# LRFDRFE register map
Vendor: Texas Instruments
Peripheral module from a debugger description file (folder CC27xxx7).
Registers are 32-bit, access per field, reset 0x0 unless marked. A register's access mark holds for its fields unless they carry their own. Offsets are as the file gives them; lines under a group give offsets from that group; [hi:lo] are bit positions; {n}, {i} and the like mark numbered series; 'fields as' and 'values as' point back to an identical list; <NAME> marks a mode.

## LRFDRFE (part 1 of 2)
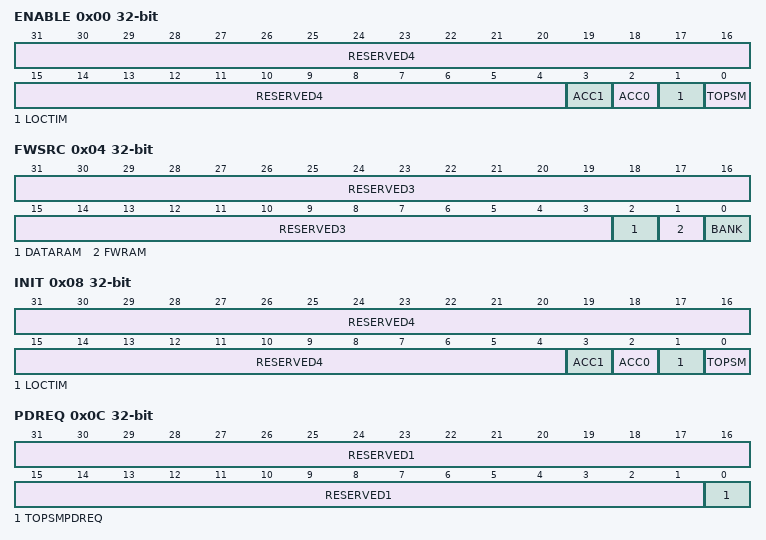
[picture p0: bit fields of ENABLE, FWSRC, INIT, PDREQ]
0x00 ENABLE — Internal. Only to be used through TI provided API.
  [31:4] RESERVED4 ro — Internal. Only to be used through TI provided API.
  [3] ACC1 rw — Internal. Only to be used through TI provided API.
    1=EN (Internal. Only to be used through TI provided API.); 0=DIS (Internal. Only to be used through TI provided API.)
  [2] ACC0 rw — Internal. Only to be used through TI provided API.
    values as ACC1
  [1] LOCTIM rw — Internal. Only to be used through TI provided API.
    values as ACC1
  [0] TOPSM rw — Internal. Only to be used through TI provided API.
    values as ACC1
0x04 FWSRC — Internal. Only to be used through TI provided API.
  [31:3] RESERVED3 ro — Internal. Only to be used through TI provided API.
  [2] DATARAM rw — Internal. Only to be used through TI provided API.
    1=S2RRAM (Internal. Only to be used through TI provided API.); 0=RFERAM (Internal. Only to be used through TI provided API.)
  [1] FWRAM rw — Internal. Only to be used through TI provided API.
    values as DATARAM
  [0] BANK rw — Internal. Only to be used through TI provided API.
    1=ONE (Internal. Only to be used through TI provided API.); 0=ZERO (Internal. Only to be used through TI provided API.)
0x08 INIT — Internal. Only to be used through TI provided API.
  [31:4] RESERVED4 ro — Internal. Only to be used through TI provided API.
  [3] ACC1 wo — Internal. Only to be used through TI provided API.
    1=RESET (Internal. Only to be used through TI provided API.); 0=NO_EFFECT (Internal. Only to be used through TI provided API.)
  [2] ACC0 wo — Internal. Only to be used through TI provided API.
    values as ACC1
  [1] LOCTIM wo — Internal. Only to be used through TI provided API.
    values as ACC1
  [0] TOPSM wo — Internal. Only to be used through TI provided API.
    values as ACC1
0x0C PDREQ — Internal. Only to be used through TI provided API.
  [31:1] RESERVED1 ro — Internal. Only to be used through TI provided API.
  [0] TOPSMPDREQ rw — Internal. Only to be used through TI provided API.
    values as FWSRC.BANK
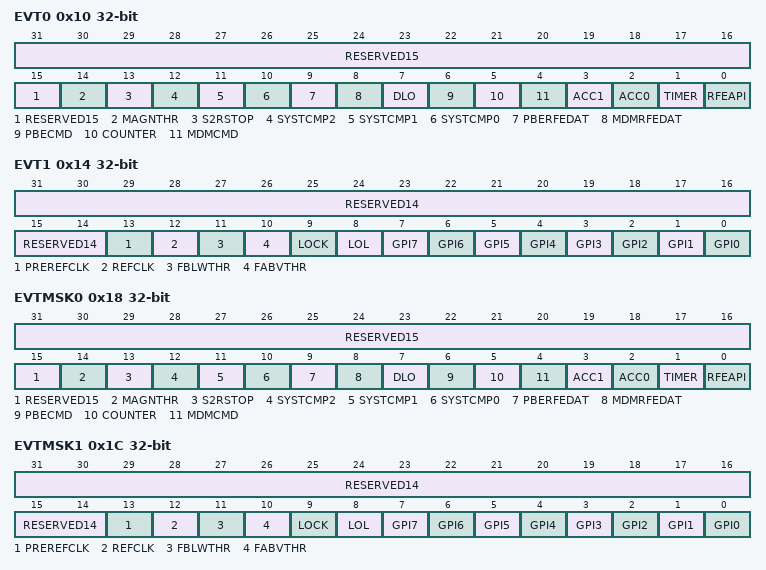
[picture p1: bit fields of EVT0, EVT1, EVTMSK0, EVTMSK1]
0x10 EVT0 ro — Internal. Only to be used through TI provided API.
  [31:15] RESERVED15 — Internal. Only to be used through TI provided API.
  [14] MAGNTHR — Internal. Only to be used through TI provided API.
    values as FWSRC.BANK
  [13] S2RSTOP — Internal. Only to be used through TI provided API.
    values as FWSRC.BANK
  [12] SYSTCMP2 — Internal. Only to be used through TI provided API.
    values as FWSRC.BANK
  [11] SYSTCMP1 — Internal. Only to be used through TI provided API.
    values as FWSRC.BANK
  [10] SYSTCMP0 — Internal. Only to be used through TI provided API.
    values as FWSRC.BANK
  [9] PBERFEDAT — Internal. Only to be used through TI provided API.
    values as FWSRC.BANK
  [8] MDMRFEDAT — Internal. Only to be used through TI provided API.
    values as FWSRC.BANK
  [7] DLO — Internal. Only to be used through TI provided API.
    values as FWSRC.BANK
  [6] PBECMD — Internal. Only to be used through TI provided API.
    values as FWSRC.BANK
  [5] COUNTER — Internal. Only to be used through TI provided API.
    values as FWSRC.BANK
  [4] MDMCMD — Internal. Only to be used through TI provided API.
    values as FWSRC.BANK
  [3] ACC1 — Internal. Only to be used through TI provided API.
    values as FWSRC.BANK
  [2] ACC0 — Internal. Only to be used through TI provided API.
    values as FWSRC.BANK
  [1] TIMER — Internal. Only to be used through TI provided API.
    values as FWSRC.BANK
  [0] RFEAPI — Internal. Only to be used through TI provided API.
    values as FWSRC.BANK
0x14 EVT1 ro — Internal. Only to be used through TI provided API.
  [31:14] RESERVED14 — Internal. Only to be used through TI provided API.
  [13] PREREFCLK — Internal. Only to be used through TI provided API.
    values as FWSRC.BANK
  [12] REFCLK — Internal. Only to be used through TI provided API.
    values as FWSRC.BANK
  [11] FBLWTHR — Internal. Only to be used through TI provided API.
    values as FWSRC.BANK
  [10] FABVTHR — Internal. Only to be used through TI provided API.
    values as FWSRC.BANK
  [9] LOCK — Internal. Only to be used through TI provided API.
    values as FWSRC.BANK
  [8] LOL — Internal. Only to be used through TI provided API.
    values as FWSRC.BANK
  [n] GPI{n} (n=0..7) — Internal. Only to be used through TI provided API.
    values as FWSRC.BANK
0x18 EVTMSK0 — Internal. Only to be used through TI provided API.
  [31:15] RESERVED15 ro — Internal. Only to be used through TI provided API.
  [14] MAGNTHR rw — Internal. Only to be used through TI provided API.
    values as ENABLE.ACC1
  [13] S2RSTOP rw — Internal. Only to be used through TI provided API.
    values as ENABLE.ACC1
  [12] SYSTCMP2 rw — Internal. Only to be used through TI provided API.
    values as ENABLE.ACC1
  [11] SYSTCMP1 rw — Internal. Only to be used through TI provided API.
    values as ENABLE.ACC1
  [10] SYSTCMP0 rw — Internal. Only to be used through TI provided API.
    values as ENABLE.ACC1
  [9] PBERFEDAT rw — Internal. Only to be used through TI provided API.
    values as ENABLE.ACC1
  [8] MDMRFEDAT rw — Internal. Only to be used through TI provided API.
    values as ENABLE.ACC1
  [7] DLO rw — Internal. Only to be used through TI provided API.
    values as ENABLE.ACC1
  [6] PBECMD rw — Internal. Only to be used through TI provided API.
    values as ENABLE.ACC1
  [5] COUNTER rw — Internal. Only to be used through TI provided API.
    values as ENABLE.ACC1
  [4] MDMCMD rw — Internal. Only to be used through TI provided API.
    values as ENABLE.ACC1
  [3] ACC1 rw — Internal. Only to be used through TI provided API.
    values as ENABLE.ACC1
  [2] ACC0 rw — Internal. Only to be used through TI provided API.
    values as ENABLE.ACC1
  [1] TIMER rw — Internal. Only to be used through TI provided API.
    values as ENABLE.ACC1
  [0] RFEAPI rw — Internal. Only to be used through TI provided API.
    values as ENABLE.ACC1
0x1C EVTMSK1 — Internal. Only to be used through TI provided API.
  [31:14] RESERVED14 ro — Internal. Only to be used through TI provided API.
  [13] PREREFCLK rw — Internal. Only to be used through TI provided API.
    values as ENABLE.ACC1
  [12] REFCLK rw — Internal. Only to be used through TI provided API.
    values as ENABLE.ACC1
  [11] FBLWTHR rw — Internal. Only to be used through TI provided API.
    values as ENABLE.ACC1
  [10] FABVTHR rw — Internal. Only to be used through TI provided API.
    values as ENABLE.ACC1
  [9] LOCK rw — Internal. Only to be used through TI provided API.
    values as ENABLE.ACC1
  [8] LOL rw — Internal. Only to be used through TI provided API.
    values as ENABLE.ACC1
  [n] GPI{n} rw (n=0..7) — Internal. Only to be used through TI provided API.
    values as ENABLE.ACC1
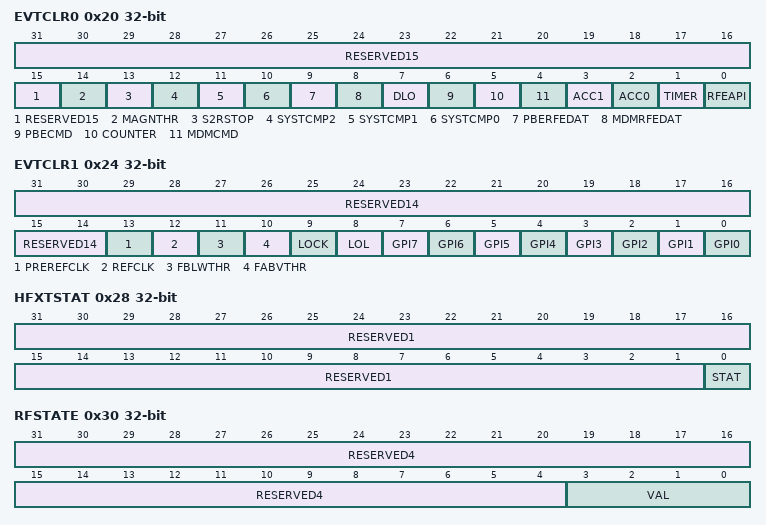
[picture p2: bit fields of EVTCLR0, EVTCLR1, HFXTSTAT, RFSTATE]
0x20 EVTCLR0 — Internal. Only to be used through TI provided API.
  [31:15] RESERVED15 ro — Internal. Only to be used through TI provided API.
  [14] MAGNTHR wo — Internal. Only to be used through TI provided API.
    values as FWSRC.BANK
  [13] S2RSTOP wo — Internal. Only to be used through TI provided API.
    values as FWSRC.BANK
  [12] SYSTCMP2 wo — Internal. Only to be used through TI provided API.
    values as FWSRC.BANK
  [11] SYSTCMP1 wo — Internal. Only to be used through TI provided API.
    values as FWSRC.BANK
  [10] SYSTCMP0 wo — Internal. Only to be used through TI provided API.
    values as FWSRC.BANK
  [9] PBERFEDAT wo — Internal. Only to be used through TI provided API.
    values as FWSRC.BANK
  [8] MDMRFEDAT wo — Internal. Only to be used through TI provided API.
    values as FWSRC.BANK
  [7] DLO wo — Internal. Only to be used through TI provided API.
    values as FWSRC.BANK
  [6] PBECMD wo — Internal. Only to be used through TI provided API.
    values as FWSRC.BANK
  [5] COUNTER wo — Internal. Only to be used through TI provided API.
    values as FWSRC.BANK
  [4] MDMCMD wo — Internal. Only to be used through TI provided API.
    values as FWSRC.BANK
  [3] ACC1 wo — Internal. Only to be used through TI provided API.
    values as FWSRC.BANK
  [2] ACC0 wo — Internal. Only to be used through TI provided API.
    values as FWSRC.BANK
  [1] TIMER wo — Internal. Only to be used through TI provided API.
    values as FWSRC.BANK
  [0] RFEAPI wo — Internal. Only to be used through TI provided API.
    values as FWSRC.BANK
0x24 EVTCLR1 — Internal. Only to be used through TI provided API.
  [31:14] RESERVED14 ro — Internal. Only to be used through TI provided API.
  [13] PREREFCLK wo — Internal. Only to be used through TI provided API.
    values as FWSRC.BANK
  [12] REFCLK wo — Internal. Only to be used through TI provided API.
    values as FWSRC.BANK
  [11] FBLWTHR wo — Internal. Only to be used through TI provided API.
    values as FWSRC.BANK
  [10] FABVTHR wo — Internal. Only to be used through TI provided API.
    values as FWSRC.BANK
  [9] LOCK wo — Internal. Only to be used through TI provided API.
    values as FWSRC.BANK
  [8] LOL wo — Internal. Only to be used through TI provided API.
    values as FWSRC.BANK
  [n] GPI{n} wo (n=0..7) — Internal. Only to be used through TI provided API.
    values as FWSRC.BANK
0x28 HFXTSTAT ro — Internal. Only to be used through TI provided API.
  [31:1] RESERVED1 — Internal. Only to be used through TI provided API.
  [0] STAT — Internal. Only to be used through TI provided API.
    1=QUAL (Internal. Only to be used through TI provided API.); 0=NONQUAL (Internal. Only to be used through TI provided API.)
0x30 RFSTATE — Internal. Only to be used through TI provided API.
  [31:4] RESERVED4 ro — Internal. Only to be used through TI provided API.
  [3:0] VAL rw — Internal. Only to be used through TI provided API.
    3=RX (Internal. Only to be used through TI provided API.); 2=TX (Internal. Only to be used through TI provided API.); 1=SYNTH (Internal. Only to be used through TI provided API.); 0=IDLE (Internal. Only to be used through TI provided API.)
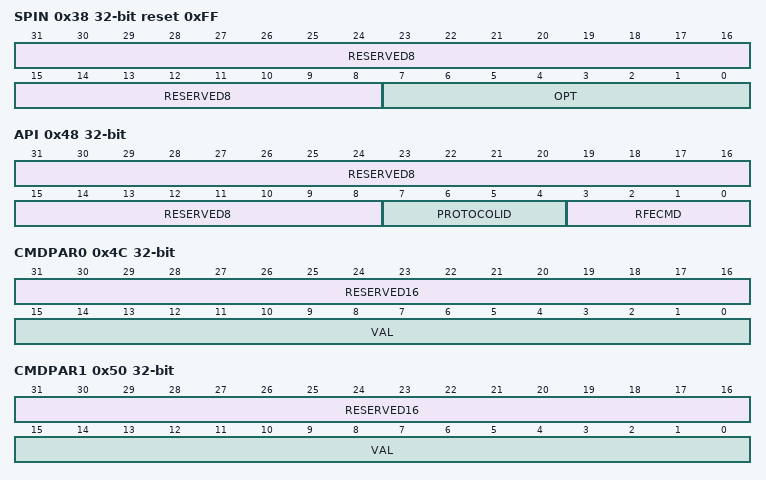
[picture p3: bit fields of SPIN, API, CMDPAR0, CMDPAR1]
0x38 SPIN ro reset 0xFF — Internal. Only to be used through TI provided API.
  [31:8] RESERVED8 — Internal. Only to be used through TI provided API.
  [7:0] OPT — Internal. Only to be used through TI provided API.
    255=ALLONES (Internal. Only to be used through TI provided API.); 0=ALLZEROS (Internal. Only to be used through TI provided API.)
0x48 API ro — Internal. Only to be used through TI provided API.
  [31:8] RESERVED8 — Internal. Only to be used through TI provided API.
  [7:4] PROTOCOLID — Internal. Only to be used through TI provided API.
    15=ALLONES (Internal. Only to be used through TI provided API.); 0=ALLZEROS (Internal. Only to be used through TI provided API.)
  [3:0] RFECMD — Internal. Only to be used through TI provided API.
    values as PROTOCOLID
0x4C CMDPAR0 ro — Internal. Only to be used through TI provided API.
  [31:16] RESERVED16 — Internal. Only to be used through TI provided API.
  [15:0] VAL — Internal. Only to be used through TI provided API.
    0xFFFF=ALLONES (Internal. Only to be used through TI provided API.); 0=ALLZEROS (Internal. Only to be used through TI provided API.)
0x50 CMDPAR1 ro — Internal. Only to be used through TI provided API.
  fields as CMDPAR0
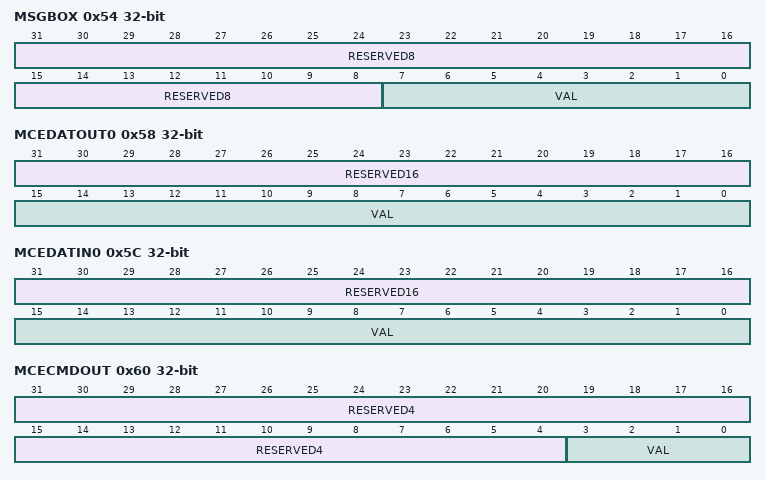
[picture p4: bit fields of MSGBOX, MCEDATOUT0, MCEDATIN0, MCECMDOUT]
0x54 MSGBOX — Internal. Only to be used through TI provided API.
  [31:8] RESERVED8 ro — Internal. Only to be used through TI provided API.
  [7:0] VAL rw — Internal. Only to be used through TI provided API.
    values as SPIN.OPT
0x58 MCEDATOUT0 — Internal. Only to be used through TI provided API.
  [31:16] RESERVED16 ro — Internal. Only to be used through TI provided API.
  [15:0] VAL rw — Internal. Only to be used through TI provided API.
    values as CMDPAR0.VAL
0x5C MCEDATIN0 ro — Internal. Only to be used through TI provided API.
  fields as CMDPAR0
0x60 MCECMDOUT — Internal. Only to be used through TI provided API.
  [31:4] RESERVED4 ro — Internal. Only to be used through TI provided API.
  [3:0] VAL rw — Internal. Only to be used through TI provided API.
    values as API.PROTOCOLID
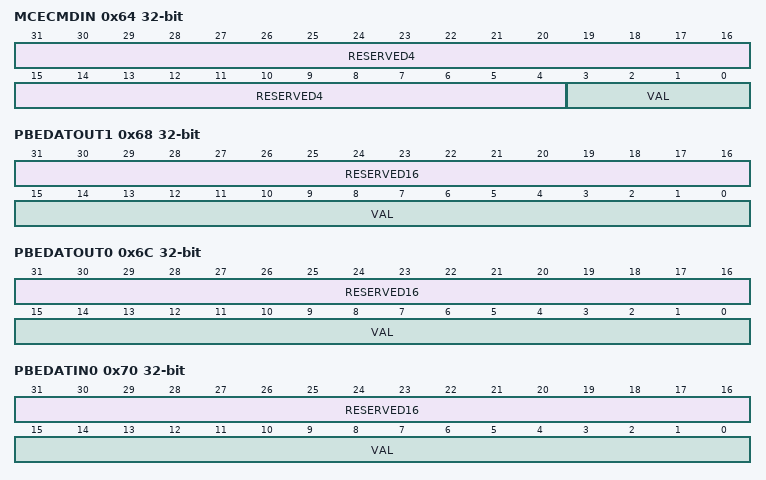
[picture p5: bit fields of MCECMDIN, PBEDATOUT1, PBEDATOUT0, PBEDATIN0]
0x64 MCECMDIN ro — Internal. Only to be used through TI provided API.
  [31:4] RESERVED4 — Internal. Only to be used through TI provided API.
  [3:0] VAL — Internal. Only to be used through TI provided API.
    values as API.PROTOCOLID
0x68 PBEDATOUT1 — Internal. Only to be used through TI provided API.
  fields as MCEDATOUT0
0x6C PBEDATOUT0 — Internal. Only to be used through TI provided API.
  fields as MCEDATOUT0
0x70 PBEDATIN0 ro — Internal. Only to be used through TI provided API.
  fields as CMDPAR0
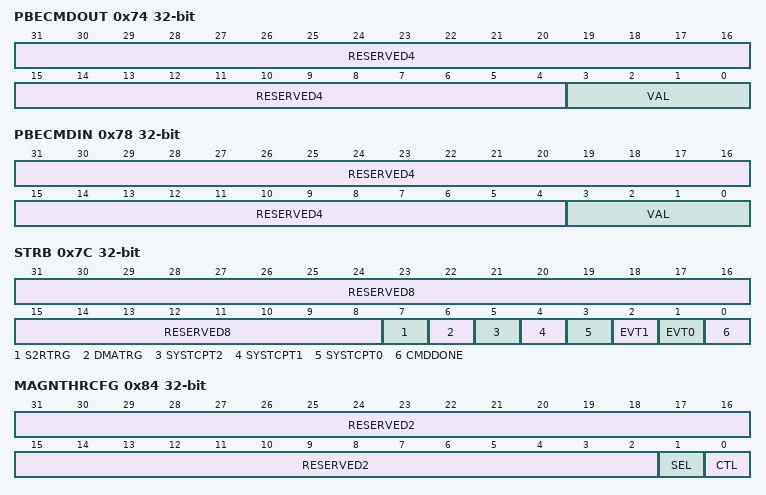
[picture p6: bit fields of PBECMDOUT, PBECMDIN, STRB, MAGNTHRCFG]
0x74 PBECMDOUT — Internal. Only to be used through TI provided API.
  fields as MCECMDOUT
0x78 PBECMDIN ro — Internal. Only to be used through TI provided API.
  fields as MCECMDIN
0x7C STRB — Internal. Only to be used through TI provided API.
  [31:8] RESERVED8 ro — Internal. Only to be used through TI provided API.
  [7] S2RTRG wo — Internal. Only to be used through TI provided API.
    values as FWSRC.BANK
  [6] DMATRG wo — Internal. Only to be used through TI provided API.
    values as FWSRC.BANK
  [5] SYSTCPT2 wo — Internal. Only to be used through TI provided API.
    values as FWSRC.BANK
  [4] SYSTCPT1 wo — Internal. Only to be used through TI provided API.
    values as FWSRC.BANK
  [3] SYSTCPT0 wo — Internal. Only to be used through TI provided API.
    values as FWSRC.BANK
  [2] EVT1 wo — Internal. Only to be used through TI provided API.
    values as FWSRC.BANK
  [1] EVT0 wo — Internal. Only to be used through TI provided API.
    values as FWSRC.BANK
  [0] CMDDONE wo — Internal. Only to be used through TI provided API.
    1=YES (Internal. Only to be used through TI provided API.); 0=NO (Internal. Only to be used through TI provided API.)
0x84 MAGNTHRCFG — Internal. Only to be used through TI provided API.
  [31:2] RESERVED2 ro — Internal. Only to be used through TI provided API.
  [1] SEL rw — Internal. Only to be used through TI provided API.
    1=MAGNACC1 (Internal. Only to be used through TI provided API.); 0=MAGNACC0 (Internal. Only to be used through TI provided API.)
  [0] CTL rw — Internal. Only to be used through TI provided API.
    values as ENABLE.ACC1
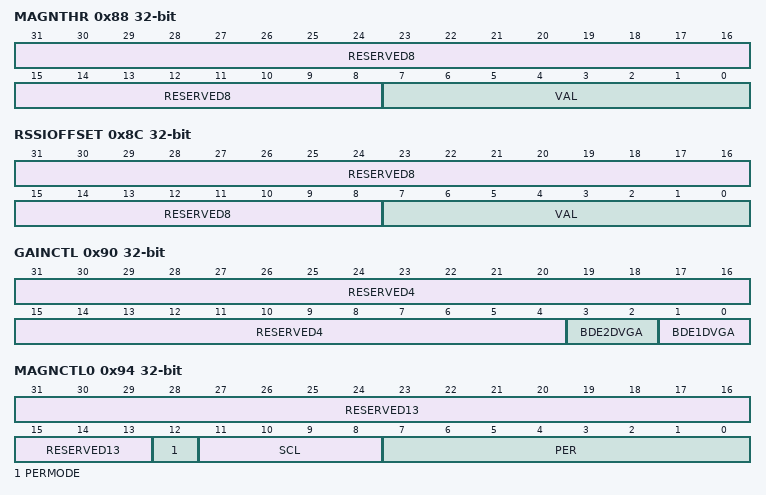
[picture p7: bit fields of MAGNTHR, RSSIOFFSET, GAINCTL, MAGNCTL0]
0x88 MAGNTHR — Internal. Only to be used through TI provided API.
  fields as MSGBOX
0x8C RSSIOFFSET — Internal. Only to be used through TI provided API.
  fields as MSGBOX
0x90 GAINCTL — Internal. Only to be used through TI provided API.
  [31:4] RESERVED4 ro — Internal. Only to be used through TI provided API.
  [3:2] BDE2DVGA rw — Internal. Only to be used through TI provided API.
    3=GAIN8 (Internal. Only to be used through TI provided API.); 2=GAIN4 (Internal. Only to be used through TI provided API.); 1=GAIN2 (Internal. Only to be used through TI provided API.); 0=GAIN1 (Internal. Only to be used through TI provided API.)
  [1:0] BDE1DVGA rw — Internal. Only to be used through TI provided API.
    values as BDE2DVGA
0x94 MAGNCTL0 — Internal. Only to be used through TI provided API.
  [31:13] RESERVED13 ro — Internal. Only to be used through TI provided API.
  [12] PERMODE rw — Internal. Only to be used through TI provided API.
    1=PERIODIC (Internal. Only to be used through TI provided API.); 0=ONESHOT (Internal. Only to be used through TI provided API.)
  [11:8] SCL rw — Internal. Only to be used through TI provided API.
    8=DIV256 (Internal. Only to be used through TI provided API.); 7=DIV128 (Internal. Only to be used through TI provided API.); 6=DIV64 (Internal. Only to be used through TI provided API.); 5=DIV32 (Internal. Only to be used through TI provided API.); 4=DIV16 (Internal. Only to be used through TI provided API.); 3=DIV8 (Internal. Only to be used through TI provided API.); 2=DIV4 (Internal. Only to be used through TI provided API.); 1=DIV2 (Internal. Only to be used through TI provided API.); 0=DIV1 (Internal. Only to be used through TI provided API.)
  [7:0] PER rw — Internal. Only to be used through TI provided API.
    values as SPIN.OPT
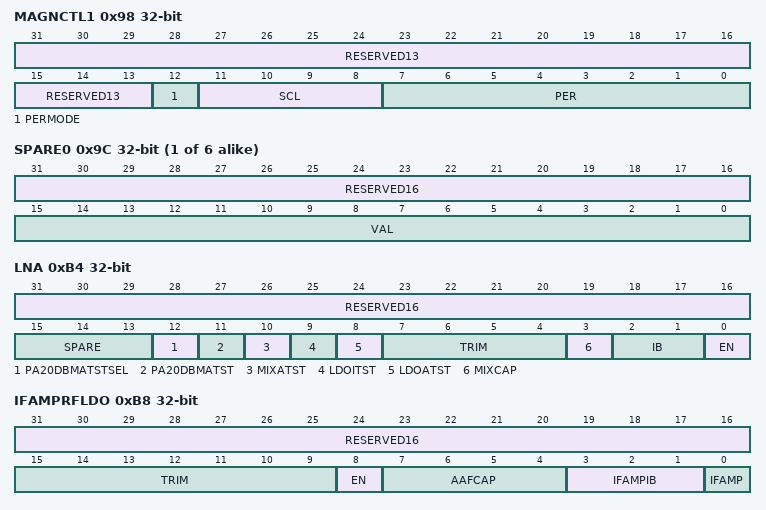
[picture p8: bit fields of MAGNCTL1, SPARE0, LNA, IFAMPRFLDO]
0x98 MAGNCTL1 — Internal. Only to be used through TI provided API.
  fields as MAGNCTL0
{0x9C+4i} SPARE{i} (i=0..5) — Internal. Only to be used through TI provided API.
  fields as MCEDATOUT0
0xB4 LNA — Internal. Only to be used through TI provided API.
  [31:16] RESERVED16 ro — Internal. Only to be used through TI provided API.
  [15:13] SPARE rw — Internal. Only to be used through TI provided API.
    values as ENABLE.ACC1
  [12] PA20DBMATSTSEL rw — Internal. Only to be used through TI provided API.
    1=SECOND (Internal. Only to be used through TI provided API.); 0=FIRST (Internal. Only to be used through TI provided API.)
  [11] PA20DBMATST rw — Internal. Only to be used through TI provided API.
    values as ENABLE.ACC1
  [10] MIXATST rw — Internal. Only to be used through TI provided API.
    values as ENABLE.ACC1
  [9] LDOITST rw — Internal. Only to be used through TI provided API.
    values as ENABLE.ACC1
  [8] LDOATST rw — Internal. Only to be used through TI provided API.
    values as ENABLE.ACC1
  [7:4] TRIM rw — Internal. Only to be used through TI provided API.
    15=ONES (Internal. Only to be used through TI provided API.); 0=ZEROS (Internal. Only to be used through TI provided API.)
  [3] MIXCAP rw — Internal. Only to be used through TI provided API.
    values as ENABLE.ACC1
  [2:1] IB rw — Internal. Only to be used through TI provided API.
    3=MAX (Internal. Only to be used through TI provided API.); 0=MIN (Internal. Only to be used through TI provided API.)
  [0] EN rw — Internal. Only to be used through TI provided API.
    1=ON (Internal. Only to be used through TI provided API.); 0=OFF (Internal. Only to be used through TI provided API.)
0xB8 IFAMPRFLDO — Internal. Only to be used through TI provided API.
  [31:16] RESERVED16 ro — Internal. Only to be used through TI provided API.
  [15:9] TRIM rw — Internal. Only to be used through TI provided API.
    127=BYPASS (Internal. Only to be used through TI provided API.); 126=MAX (Internal. Only to be used through TI provided API.); 0=MIN (Internal. Only to be used through TI provided API.)
  [8] EN rw — Internal. Only to be used through TI provided API.
    values as ENABLE.ACC1
  [7:4] AAFCAP rw — Internal. Only to be used through TI provided API.
    15=MAX (Internal. Only to be used through TI provided API.); 0=MIN (Internal. Only to be used through TI provided API.)
  [3:1] IFAMPIB rw — Internal. Only to be used through TI provided API.
    7=MAX (Internal. Only to be used through TI provided API.); 0=MIN (Internal. Only to be used through TI provided API.)
  [0] IFAMP rw — Internal. Only to be used through TI provided API.
    values as ENABLE.ACC1
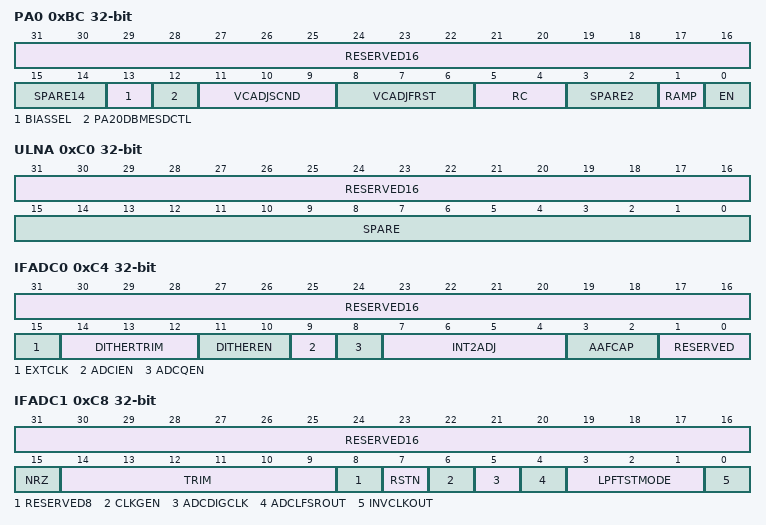
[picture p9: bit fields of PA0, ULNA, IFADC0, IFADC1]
0xBC PA0 — Internal. Only to be used through TI provided API.
  [31:16] RESERVED16 ro — Internal. Only to be used through TI provided API.
  [15:14] SPARE14 rw — Internal. Only to be used through TI provided API.
    values as LNA.IB
  [13] BIASSEL rw — Internal. Only to be used through TI provided API.
    values as FWSRC.BANK
  [12] PA20DBMESDCTL rw — Internal. Only to be used through TI provided API.
    values as FWSRC.BANK
  [11:9] VCADJSCND rw — Internal. Only to be used through TI provided API.
    values as IFAMPRFLDO.IFAMPIB
  [8:6] VCADJFRST rw — Internal. Only to be used through TI provided API.
    values as IFAMPRFLDO.IFAMPIB
  [5:4] RC rw — Internal. Only to be used through TI provided API.
    values as LNA.IB
  [3:2] SPARE2 rw — Internal. Only to be used through TI provided API.
    values as LNA.IB
  [1] RAMP rw — Internal. Only to be used through TI provided API.
    1=UP (Internal. Only to be used through TI provided API.); 0=DOWN (Internal. Only to be used through TI provided API.)
  [0] EN rw — Internal. Only to be used through TI provided API.
    values as ENABLE.ACC1
0xC0 ULNA — Internal. Only to be used through TI provided API.
  [31:16] RESERVED16 ro — Internal. Only to be used through TI provided API.
  [15:0] SPARE rw — Internal. Only to be used through TI provided API.
    values as CMDPAR0.VAL
0xC4 IFADC0 — Internal. Only to be used through TI provided API.
  [31:16] RESERVED16 ro — Internal. Only to be used through TI provided API.
  [15] EXTCLK rw — Internal. Only to be used through TI provided API.
    values as ENABLE.ACC1
  [14:12] DITHERTRIM rw — Internal. Only to be used through TI provided API.
    7=ONES (Internal. Only to be used through TI provided API.); 0=ZEROS (Internal. Only to be used through TI provided API.)
  [11:10] DITHEREN rw — Internal. Only to be used through TI provided API.
    3=ENG (Internal. Only to be used through TI provided API.); 2=ENSD (Internal. Only to be used through TI provided API.); 1=ENS (Internal. Only to be used through TI provided API.); 0=DIS (Internal. Only to be used through TI provided API.)
  [9] ADCIEN rw — Internal. Only to be used through TI provided API.
    values as ENABLE.ACC1
  [8] ADCQEN rw — Internal. Only to be used through TI provided API.
    values as ENABLE.ACC1
  [7:4] INT2ADJ rw — Internal. Only to be used through TI provided API.
    values as LNA.TRIM
  [3:2] AAFCAP rw — Internal. Only to be used through TI provided API.
    values as DITHEREN
  [1:0] RESERVED rw — Internal. Only to be used through TI provided API.
    3=ONES (Internal. Only to be used through TI provided API.); 0=ZEROS (Internal. Only to be used through TI provided API.)
0xC8 IFADC1 — Internal. Only to be used through TI provided API.
  [31:16] RESERVED16 ro — Internal. Only to be used through TI provided API.
  [15] NRZ rw — Internal. Only to be used through TI provided API.
    values as ENABLE.ACC1
  [14:9] TRIM rw — Internal. Only to be used through TI provided API.
    63=ONES (Internal. Only to be used through TI provided API.); 0=ZEROS (Internal. Only to be used through TI provided API.)
  [8] RESERVED8 rw — Internal. Only to be used through TI provided API.
    values as ENABLE.ACC1
  [7] RSTN rw — Internal. Only to be used through TI provided API.
    1=DIS (Internal. Only to be used through TI provided API.); 0=EN (Internal. Only to be used through TI provided API.)
  [6] CLKGEN rw — Internal. Only to be used through TI provided API.
    values as ENABLE.ACC1
  [5] ADCDIGCLK rw — Internal. Only to be used through TI provided API.
    values as ENABLE.ACC1
  [4] ADCLFSROUT rw — Internal. Only to be used through TI provided API.
    values as ENABLE.ACC1
  [3:1] LPFTSTMODE rw — Internal. Only to be used through TI provided API.
    values as ENABLE.ACC1
  [0] INVCLKOUT rw — Internal. Only to be used through TI provided API.
    values as ENABLE.ACC1
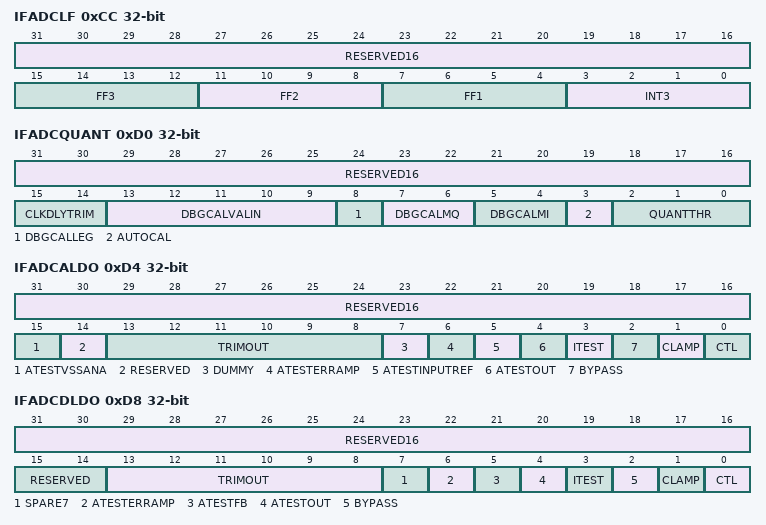
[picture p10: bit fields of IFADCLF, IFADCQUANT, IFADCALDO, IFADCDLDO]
0xCC IFADCLF — Internal. Only to be used through TI provided API.
  [31:16] RESERVED16 ro — Internal. Only to be used through TI provided API.
  [15:12] FF3 rw — Internal. Only to be used through TI provided API.
    values as LNA.TRIM
  [11:8] FF2 rw — Internal. Only to be used through TI provided API.
    values as LNA.TRIM
  [7:4] FF1 rw — Internal. Only to be used through TI provided API.
    values as LNA.TRIM
  [3:0] INT3 rw — Internal. Only to be used through TI provided API.
    values as LNA.TRIM
0xD0 IFADCQUANT — Internal. Only to be used through TI provided API.
  [31:16] RESERVED16 ro — Internal. Only to be used through TI provided API.
  [15:14] CLKDLYTRIM rw — Internal. Only to be used through TI provided API.
    values as IFADC0.RESERVED
  [13:9] DBGCALVALIN rw — Internal. Only to be used through TI provided API.
    31=ONES (Internal. Only to be used through TI provided API.); 0=ZEROS (Internal. Only to be used through TI provided API.)
  [8] DBGCALLEG rw — Internal. Only to be used through TI provided API.
    1=NEG (Internal. Only to be used through TI provided API.); 0=POS (Internal. Only to be used through TI provided API.)
  [7:6] DBGCALMQ rw — Internal. Only to be used through TI provided API.
    3=DBGCAL_QMODB (Internal. Only to be used through TI provided API.); 2=DBGCAL_QMODP (Internal. Only to be used through TI provided API.); 1=DBGCAL_QMODN (Internal. Only to be used through TI provided API.); 0=DBGCAL_QMODZ (Internal. Only to be used through TI provided API.)
  [5:4] DBGCALMI rw — Internal. Only to be used through TI provided API.
    3=DBGCAL_IMODB (Internal. Only to be used through TI provided API.); 2=DBGCAL_IMODP (Internal. Only to be used through TI provided API.); 1=DBGCAL_IMODN (Internal. Only to be used through TI provided API.); 0=DBGCAL_IMODZ (Internal. Only to be used through TI provided API.)
  [3] AUTOCAL rw — Internal. Only to be used through TI provided API.
    values as ENABLE.ACC1
  [2:0] QUANTTHR rw — Internal. Only to be used through TI provided API.
    values as IFADC0.DITHERTRIM
0xD4 IFADCALDO — Internal. Only to be used through TI provided API.
  [31:16] RESERVED16 ro — Internal. Only to be used through TI provided API.
  [15] ATESTVSSANA rw — Internal. Only to be used through TI provided API.
    values as ENABLE.ACC1
  [14] RESERVED rw — Internal. Only to be used through TI provided API.
    1=ONES (Internal. Only to be used through TI provided API.); 0=ZEROS (Internal. Only to be used through TI provided API.)
  [13:8] TRIMOUT rw — Internal. Only to be used through TI provided API.
    values as IFADC1.TRIM
  [7] DUMMY rw — Internal. Only to be used through TI provided API.
    1=DISN (Internal. Only to be used through TI provided API.); 0=ENN (Internal. Only to be used through TI provided API.)
  [6] ATESTERRAMP rw — Internal. Only to be used through TI provided API.
    values as ENABLE.ACC1
  [5] ATESTINPUTREF rw — Internal. Only to be used through TI provided API.
    values as ENABLE.ACC1
  [4] ATESTOUT rw — Internal. Only to be used through TI provided API.
    values as ENABLE.ACC1
  [3] ITEST rw — Internal. Only to be used through TI provided API.
    values as ENABLE.ACC1
  [2] BYPASS rw — Internal. Only to be used through TI provided API.
    values as ENABLE.ACC1
  [1] CLAMP rw — Internal. Only to be used through TI provided API.
    values as ENABLE.ACC1
  [0] CTL rw — Internal. Only to be used through TI provided API.
    values as ENABLE.ACC1
0xD8 IFADCDLDO — Internal. Only to be used through TI provided API.
  [31:16] RESERVED16 ro — Internal. Only to be used through TI provided API.
  [15:14] RESERVED rw — Internal. Only to be used through TI provided API.
    values as IFADC0.RESERVED
  [13:8] TRIMOUT rw — Internal. Only to be used through TI provided API.
    values as IFADC1.TRIM
  [7] SPARE7 rw — Internal. Only to be used through TI provided API.
    1=One (Internal. Only to be used through TI provided API.); 0=ZERO (Internal. Only to be used through TI provided API.)
  [6] ATESTERRAMP rw — Internal. Only to be used through TI provided API.
    values as ENABLE.ACC1
  [5] ATESTFB rw — Internal. Only to be used through TI provided API.
    values as ENABLE.ACC1
  [4] ATESTOUT rw — Internal. Only to be used through TI provided API.
    values as ENABLE.ACC1
  [3] ITEST rw — Internal. Only to be used through TI provided API.
    values as ENABLE.ACC1
  [2] BYPASS rw — Internal. Only to be used through TI provided API.
    values as ENABLE.ACC1
  [1] CLAMP rw — Internal. Only to be used through TI provided API.
    values as ENABLE.ACC1
  [0] CTL rw — Internal. Only to be used through TI provided API.
    values as ENABLE.ACC1
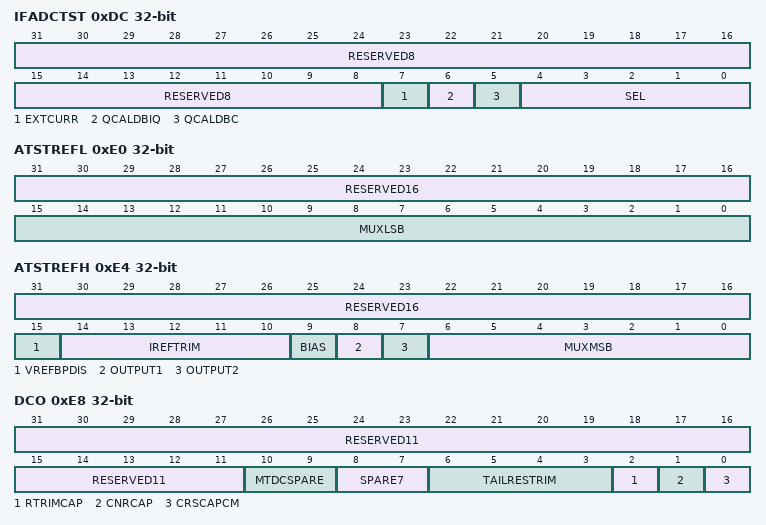
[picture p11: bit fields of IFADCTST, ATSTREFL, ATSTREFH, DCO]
0xDC IFADCTST — Internal. Only to be used through TI provided API.
  [31:8] RESERVED8 ro — Internal. Only to be used through TI provided API.
  [7] EXTCURR rw — Internal. Only to be used through TI provided API.
    values as ENABLE.ACC1
  [6] QCALDBIQ rw — Internal. Only to be used through TI provided API.
    1=COMP1 (Internal. Only to be used through TI provided API.); 0=COMP0 (Internal. Only to be used through TI provided API.)
  [5] QCALDBC rw — Internal. Only to be used through TI provided API.
    values as QCALDBIQ
  [4:0] SEL rw — Internal. Only to be used through TI provided API.
    31=EXTCLKN1 (Internal. Only to be used through TI provided API.); 0=NONE (Internal. Only to be used through TI provided API.)
0xE0 ATSTREFL — Internal. Only to be used through TI provided API.
  [31:16] RESERVED16 ro — Internal. Only to be used through TI provided API.
  [15:0] MUXLSB rw — Internal. Only to be used through TI provided API.
    0x8000=IFADC_ATB (Internal. Only to be used through TI provided API.); 0x4000=LDO_VTEST (Internal. Only to be used through TI provided API.); 0x2000=LDO_ITEST (Internal. Only to be used through TI provided API.); 0x800=PA_PEAK_OUTN (Internal. Only to be used through TI provided API.); 0x400=PA_PEAK_OUTP (Internal. Only to be used through TI provided API.); 0x200=MIX_OUTQN (Internal. Only to be used through TI provided API.); 0x100=MIX_OUTQP (Internal. Only to be used through TI provided API.); 128=MIX_OUTIN (Internal. Only to be used through TI provided API.); 64=MIX_OUTIP (Internal. Only to be used through TI provided API.); 32=FE_OUTIN_2 (Internal. Only to be used through TI provided API.); 16=FE_OUTIP_2 (Internal. Only to be used through TI provided API.); 8=FE_OUTQN (Internal. Only to be used through TI provided API.); 4=FE_OUTQP (Internal. Only to be used through TI provided API.); 2=FE_OUTIN (Internal. Only to be used through TI provided API.); 1=FE_OUTIP (Internal. Only to be used through TI provided API.); 0=DIS (Internal. Only to be used through TI provided API.)
0xE4 ATSTREFH — Internal. Only to be used through TI provided API.
  [31:16] RESERVED16 ro — Internal. Only to be used through TI provided API.
  [15] VREFBPDIS rw — Internal. Only to be used through TI provided API.
    1=BPDIS (Internal. Only to be used through TI provided API.); 0=BPEN (Internal. Only to be used through TI provided API.)
  [14:10] IREFTRIM rw — Internal. Only to be used through TI provided API.
    values as IFADCQUANT.DBGCALVALIN
  [9] BIAS rw — Internal. Only to be used through TI provided API.
    values as ENABLE.ACC1
  [8] OUTPUT1 rw — Internal. Only to be used through TI provided API.
    values as ENABLE.ACC1
  [7] OUTPUT2 rw — Internal. Only to be used through TI provided API.
    values as ENABLE.ACC1
  [6:0] MUXMSB rw — Internal. Only to be used through TI provided API.
    16=DIVBUF_NMOS_BIAS (Internal. Only to be used through TI provided API.); 8=DIVBUF_PMOS_BIAS (Internal. Only to be used through TI provided API.); 4=REFSYS_IREF (Internal. Only to be used through TI provided API.); 1=IFADC_ATB (Internal. Only to be used through TI provided API.); 0=DIS (Internal. Only to be used through TI provided API.)
0xE8 DCO — Internal. Only to be used through TI provided API.
  [31:11] RESERVED11 ro — Internal. Only to be used through TI provided API.
  [10:9] MTDCSPARE rw — Internal. Only to be used through TI provided API.
    values as IFADC1.RSTN
  [8:7] SPARE7 rw — Internal. Only to be used through TI provided API.
    values as FWSRC.BANK
  [6:3] TAILRESTRIM rw — Internal. Only to be used through TI provided API.
    values as API.PROTOCOLID
  [2] RTRIMCAP rw — Internal. Only to be used through TI provided API.
    values as ENABLE.ACC1
  [1] CNRCAP rw — Internal. Only to be used through TI provided API.
    1=_50MHZ (Internal. Only to be used through TI provided API.); 0=DEFAULT (Internal. Only to be used through TI provided API.)
  [0] CRSCAPCM rw — Internal. Only to be used through TI provided API.
    1=REDUCED (Internal. Only to be used through TI provided API.); 0=DEFAULT (Internal. Only to be used through TI provided API.)
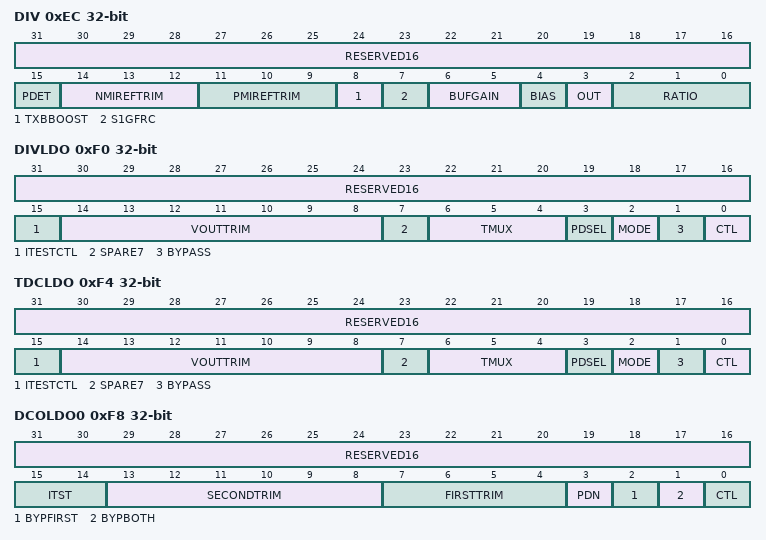
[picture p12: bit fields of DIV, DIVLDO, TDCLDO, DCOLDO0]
0xEC DIV — Internal. Only to be used through TI provided API.
  [31:16] RESERVED16 ro — Internal. Only to be used through TI provided API.
  [15] PDET rw — Internal. Only to be used through TI provided API.
    values as ENABLE.ACC1
  [14:12] NMIREFTRIM rw — Internal. Only to be used through TI provided API.
    7=ALLONES (Internal. Only to be used through TI provided API.); 0=ALLZEROS (Internal. Only to be used through TI provided API.)
  [11:9] PMIREFTRIM rw — Internal. Only to be used through TI provided API.
    values as NMIREFTRIM
  [8] TXBBOOST rw — Internal. Only to be used through TI provided API.
    1=INCREASED (Internal. Only to be used through TI provided API.); 0=DEFAULT (Internal. Only to be used through TI provided API.)
  [7] S1GFRC rw — Internal. Only to be used through TI provided API.
    values as ENABLE.ACC1
  [6:5] BUFGAIN rw — Internal. Only to be used through TI provided API.
    3=_60_PST (Internal. Only to be used through TI provided API.); 2=DONT_USE (Internal. Only to be used through TI provided API.); 1=_80_PST (Internal. Only to be used through TI provided API.); 0=MAX (Internal. Only to be used through TI provided API.)
  [4] BIAS rw — Internal. Only to be used through TI provided API.
    1=DEFAULT (Internal. Only to be used through TI provided API.); 0=ALTERNATIVE (Internal. Only to be used through TI provided API.)
  [3] OUT rw — Internal. Only to be used through TI provided API.
    1=FE_2G4 (Internal. Only to be used through TI provided API.); 0=FE_S1G (Internal. Only to be used through TI provided API.)
  [2:0] RATIO rw — Internal. Only to be used through TI provided API.
    7=DIV30 (Internal. Only to be used through TI provided API.); 6=DIV15 (Internal. Only to be used through TI provided API.); 5=DIV10 (Internal. Only to be used through TI provided API.); 4=DIV5 (Internal. Only to be used through TI provided API.); 3=DIV12 (Internal. Only to be used through TI provided API.); 2=DIV6 (Internal. Only to be used through TI provided API.); 1=DIV4 (Internal. Only to be used through TI provided API.); 0=DIV2 (Internal. Only to be used through TI provided API.)
0xF0 DIVLDO — Internal. Only to be used through TI provided API.
  [31:16] RESERVED16 ro — Internal. Only to be used through TI provided API.
  [15] ITESTCTL rw — Internal. Only to be used through TI provided API.
    values as ENABLE.ACC1
  [14:8] VOUTTRIM rw — Internal. Only to be used through TI provided API.
    127=ONES (Internal. Only to be used through TI provided API.); 0=ZEROS (Internal. Only to be used through TI provided API.)
  [7] SPARE7 rw — Internal. Only to be used through TI provided API.
    1=ONE (Internal. Only to be used through TI provided API.); 0=Zero (Internal. Only to be used through TI provided API.)
  [6:4] TMUX rw — Internal. Only to be used through TI provided API.
    4=VSSR (Internal. Only to be used through TI provided API.); 2=LDO_OUT (Internal. Only to be used through TI provided API.); 1=VDDR (Internal. Only to be used through TI provided API.); 0=OFF (Internal. Only to be used through TI provided API.)
  [3] PDSEL rw — Internal. Only to be used through TI provided API.
    1=DIODE (Internal. Only to be used through TI provided API.); 0=R (Internal. Only to be used through TI provided API.)
  [2] MODE rw — Internal. Only to be used through TI provided API.
    1=FAST (Internal. Only to be used through TI provided API.); 0=NORM (Internal. Only to be used through TI provided API.)
  [1] BYPASS rw — Internal. Only to be used through TI provided API.
    values as ENABLE.ACC1
  [0] CTL rw — Internal. Only to be used through TI provided API.
    values as ENABLE.ACC1
0xF4 TDCLDO — Internal. Only to be used through TI provided API.
  [31:16] RESERVED16 ro — Internal. Only to be used through TI provided API.
  [15] ITESTCTL rw — Internal. Only to be used through TI provided API.
    values as ENABLE.ACC1
  [14:8] VOUTTRIM rw — Internal. Only to be used through TI provided API.
    values as DIVLDO.VOUTTRIM
  [7] SPARE7 rw — Internal. Only to be used through TI provided API.
    values as IFADCDLDO.SPARE7
  [6:4] TMUX rw — Internal. Only to be used through TI provided API.
    values as DIVLDO.TMUX
  [3] PDSEL rw — Internal. Only to be used through TI provided API.
    values as DIVLDO.PDSEL
  [2] MODE rw — Internal. Only to be used through TI provided API.
    values as DIVLDO.MODE
  [1] BYPASS rw — Internal. Only to be used through TI provided API.
    values as ENABLE.ACC1
  [0] CTL rw — Internal. Only to be used through TI provided API.
    values as ENABLE.ACC1
0xF8 DCOLDO0 — Internal. Only to be used through TI provided API.
  [31:16] RESERVED16 ro — Internal. Only to be used through TI provided API.
  [15:14] ITST rw — Internal. Only to be used through TI provided API.
    3=BOTH (Internal. Only to be used through TI provided API.); 2=SECOND (Internal. Only to be used through TI provided API.); 1=FIRST (Internal. Only to be used through TI provided API.); 0=DIS (Internal. Only to be used through TI provided API.)
  [13:8] SECONDTRIM rw — Internal. Only to be used through TI provided API.
    values as IFADC1.TRIM
  [7:4] FIRSTTRIM rw — Internal. Only to be used through TI provided API.
    values as LNA.TRIM
  [3] PDN rw — Internal. Only to be used through TI provided API.
    values as ENABLE.ACC1
  [2] BYPFIRST rw — Internal. Only to be used through TI provided API.
    values as ENABLE.ACC1
  [1] BYPBOTH rw — Internal. Only to be used through TI provided API.
    values as ENABLE.ACC1
  [0] CTL rw — Internal. Only to be used through TI provided API.
    values as ENABLE.ACC1
